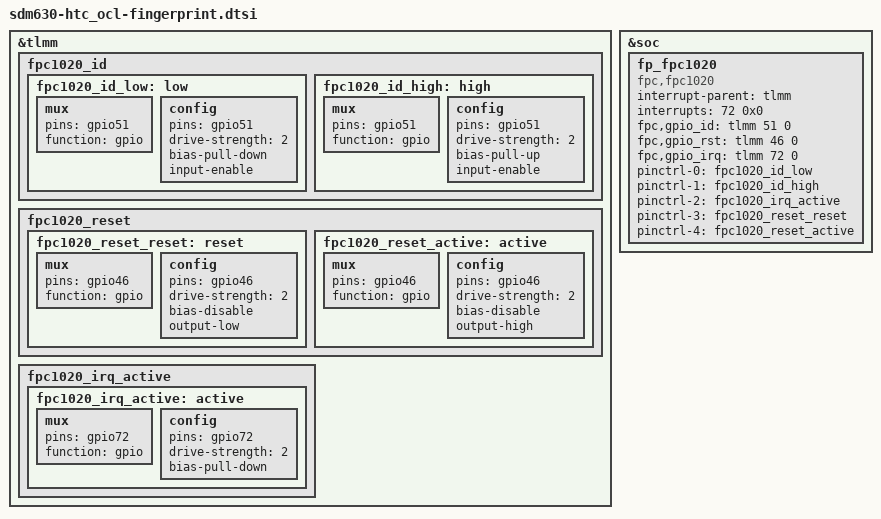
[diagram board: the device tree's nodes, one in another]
/* Copyright (c) 2016, The Linux Foundation. All rights reserved.
 *
 * This program is free software; you can redistribute it and/or modify
 * it under the terms of the GNU General Public License version 2 and
 * only version 2 as published by the Free Software Foundation.
 *
 * This program is distributed in the hope that it will be useful,
 * but WITHOUT ANY WARRANTY; without even the implied warranty of
 * MERCHANTABILITY or FITNESS FOR A PARTICULAR PURPOSE.  See the
 * GNU General Public License for more details.
 */

/*
 * msm8998-htc_ocn-fingerprint: fingerprint config
 */

&tlmm {
    fpc1020_id{
        fpc1020_id_low: low {
            mux {
                pins = "gpio51";
                function = "gpio";
            };

            config{
                pins = "gpio51";
                drive-strength = <2>;
                bias-pull-down;
                input-enable;
             };
        };
        fpc1020_id_high: high {
            mux {
                pins = "gpio51";
                function = "gpio";
            };

            config{
                pins = "gpio51";
                drive-strength = <2>;
                bias-pull-up;
                input-enable;
            };
        };
    };

    fpc1020_reset{
        fpc1020_reset_reset: reset {
            mux {
                pins = "gpio46";
                function = "gpio";
            };

            config{
                pins = "gpio46";
                drive-strength = <2>;
                bias-disable;
                output-low;
             };
        };
        fpc1020_reset_active: active {
            mux {
                pins = "gpio46";
                function = "gpio";
            };

            config{
                pins = "gpio46";
                drive-strength = <2>;
                bias-disable;
                output-high;
            };
        };
    };

     fpc1020_irq_active {
        fpc1020_irq_active: active {
            mux {
                pins = "gpio72";
                function = "gpio";
            };

            config{
                pins = "gpio72";
                drive-strength = <2>;
                bias-pull-down;
            };
        };
    };
};

&soc {
    fp_fpc1020 {
            compatible = "fpc,fpc1020";
            interrupt-parent  = <&tlmm>;
            interrupts        = <72 0x0>;
            fpc,gpio_id  = <&tlmm 51 0>;
            fpc,gpio_rst = <&tlmm 46 0>;
            fpc,gpio_irq = <&tlmm 72 0>;
            pinctrl-names     =
                        "fpc1020_id_low",
                        "fpc1020_id_high",
                        "fpc1020_irq_active",
                        "fpc1020_reset_reset",
                        "fpc1020_reset_active";

            pinctrl-0         = <&fpc1020_id_low>;
            pinctrl-1         = <&fpc1020_id_high>;
            pinctrl-2         = <&fpc1020_irq_active>;
            pinctrl-3         = <&fpc1020_reset_reset>;
            pinctrl-4         = <&fpc1020_reset_active>;
    };
};

